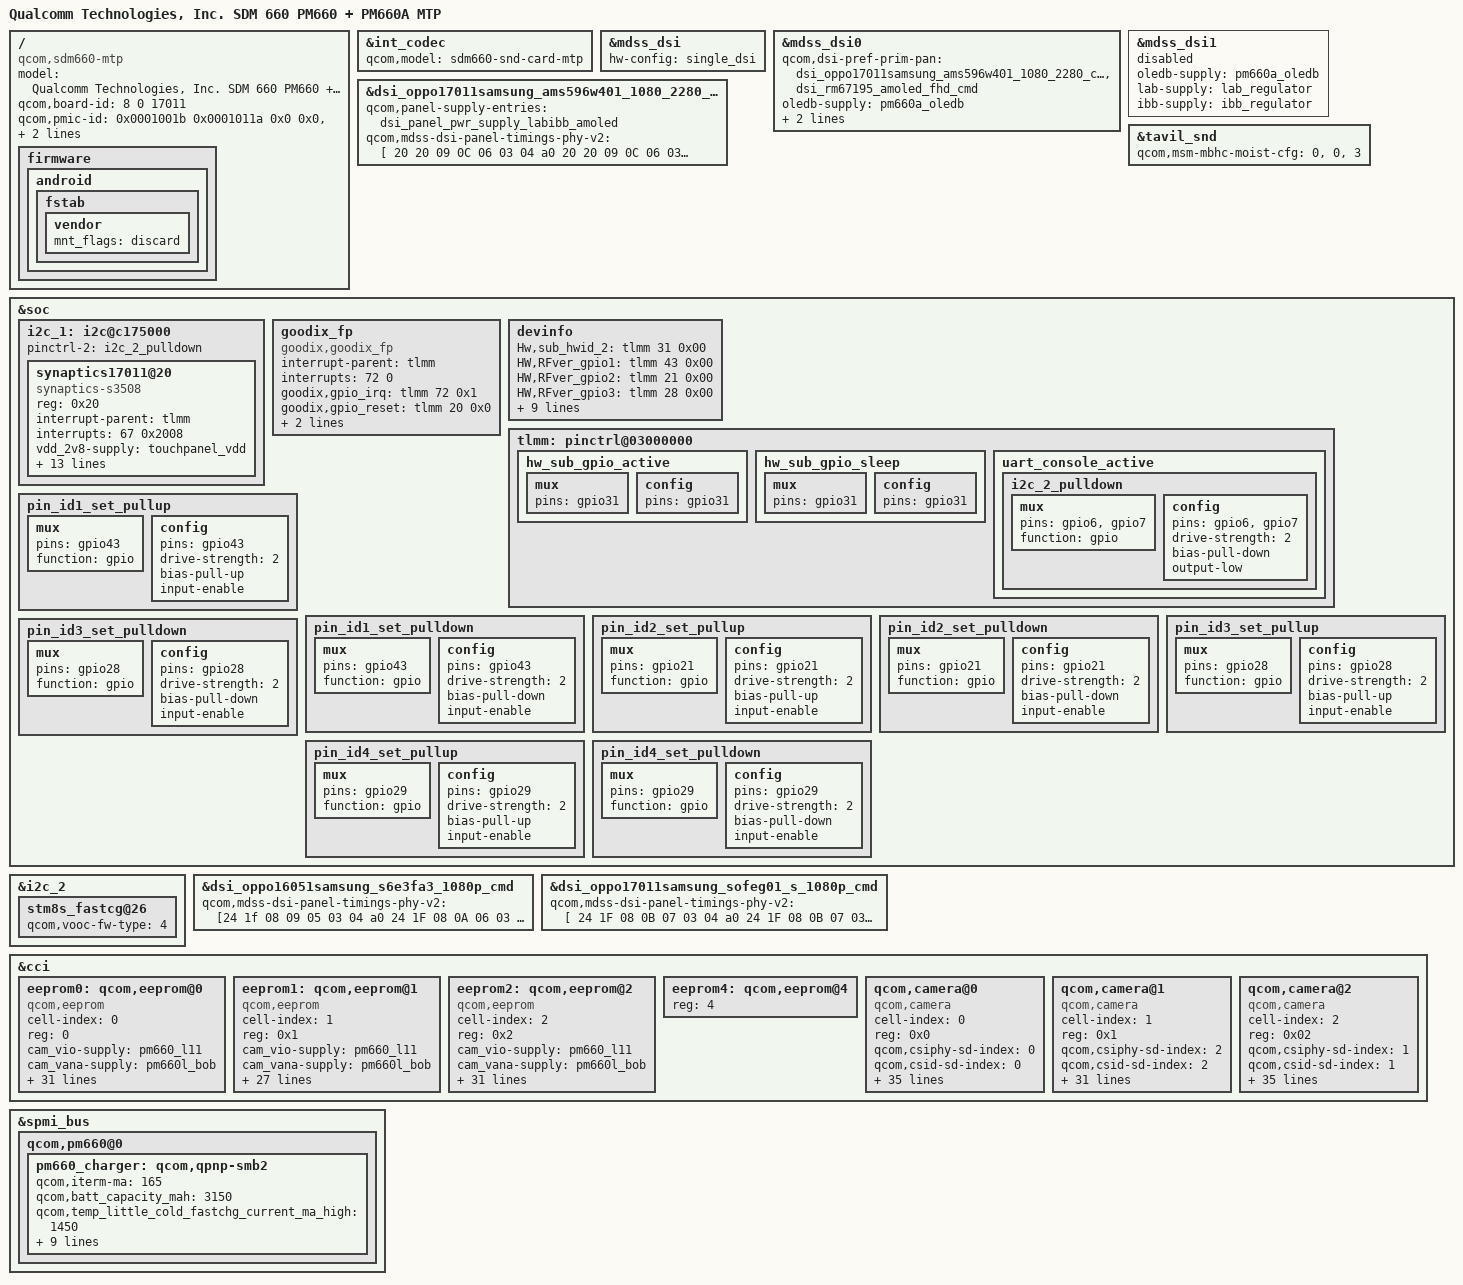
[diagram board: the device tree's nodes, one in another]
/* Copyright (c) 2016-2017, The Linux Foundation. All rights reserved.
 *
 * This program is free software; you can redistribute it and/or modify
 * it under the terms of the GNU General Public License version 2 and
 * only version 2 as published by the Free Software Foundation.
 *
 * This program is distributed in the hope that it will be useful,
 * but WITHOUT ANY WARRANTY; without even the implied warranty of
 * MERCHANTABILITY or FITNESS FOR A PARTICULAR PURPOSE.  See the
 * GNU General Public License for more details.
 */


/dts-v1/;

#include "sdm660.dtsi"
#include "sdm660-mtp.dtsi"
#include "msm-pm660a.dtsi"
//#ifndef VENDOR_EDIT
/*xiang.fei@PSW.MM.AudioDriver.Machine, 2017/01/26, Mofidy for audio config*/
//#include "sdm660-external-codec.dtsi"
//#else /* VENDOR_EDIT */
#include "sdm660-internal-codec.dtsi"
//#endif /* VENDOR_EDIT */

#include "dsi-panel-oppo17011samsung_ams596w401_1080_2280_cmd.dtsi"

/ {
	model = "Qualcomm Technologies, Inc. SDM 660 PM660 + PM660A MTP";
	compatible = "qcom,sdm660-mtp", "qcom,sdm660", "qcom,mtp";
	qcom,board-id = <8 0 17011>;
	qcom,pmic-id = <0x0001001b 0x0001011a 0x0 0x0>,
			<0x0001001b 0x0002001a 0x0 0x0>,
			<0x0001001b 0x0202001a 0x0 0x0>;
	
	firmware: firmware {
		android {
			fstab {
				vendor {
					mnt_flags = "discard";
				};
			};
		};
	};
};

//#ifdef VENDOR_EDIT
/*xiang.fei@PSW.MM.AudioDriver.Machine, 2017/01/26, Add for audio config*/
&int_codec {
	qcom,model = "sdm660-snd-card-mtp";
};
//#endif /* VENDOR_EDIT */

&mdss_dsi {
	hw-config = "single_dsi";
};

&mdss_dsi0 {
	qcom,dsi-pref-prim-pan = <&dsi_oppo17011samsung_ams596w401_1080_2280_cmd &dsi_rm67195_amoled_fhd_cmd>;
	oledb-supply = <&pm660a_oledb>;
	lab-supply = <&lab_regulator>;
	ibb-supply = <&ibb_regulator>;
};

&dsi_oppo17011samsung_ams596w401_1080_2280_cmd {
	qcom,panel-supply-entries = <&dsi_panel_pwr_supply_labibb_amoled>;
};

&mdss_dsi1 {
	status = "disabled";
	oledb-supply = <&pm660a_oledb>;
	lab-supply = <&lab_regulator>;
	ibb-supply = <&ibb_regulator>;
};

&tavil_snd {
	qcom,msm-mbhc-moist-cfg = <0>, <0>, <3>;
};

&soc {
	i2c_1: i2c@c175000 {
		status = "disabled";
	};

    i2c_1: i2c@c175000 {
		pinctrl-names = "i2c_pulldown";
		pinctrl-2 = <&i2c_2_pulldown>;
	};

	goodix_fp {
        compatible = "goodix,goodix_fp";
        interrupt-parent = <&tlmm>;
        interrupts = <72 0>;
        goodix,gpio_irq = <&tlmm 72 0x1>;
        goodix,gpio_reset = <&tlmm 20 0x0>;
        ldo5-supply = <&pm660l_l5>;  // pm660l_l5 for goodix_fp
        pinctrl-names = "default";
        pinctrl-0 = <&gpio_goodix_irq_default>;
    };

	devinfo {
		Hw,sub_hwid_2 = <&tlmm 31 0x00>;
		HW,RFver_gpio1 = <&tlmm 43 0x00>;
		HW,RFver_gpio2 = <&tlmm 21 0x00>;
		HW,RFver_gpio3 = <&tlmm 28 0x00>;
		HW,RFver_gpio4 = <&tlmm 29 0x00>;
		pinctrl-names = "gpio_HW_ID1_pullup","gpio_HW_ID1_pulldown",
						"gpio_HW_ID2_pullup", "gpio_HW_ID2_pulldown",
						"gpio_HW_ID3_pullup", "gpio_HW_ID3_pulldown",
						"gpio_HW_ID4_pullup", "gpio_HW_ID4_pulldown";
		
		pinctrl-2 = <&pin_id1_set_pullup>;
		pinctrl-3 = <&pin_id1_set_pulldown>;
		pinctrl-4 = <&pin_id2_set_pullup>;
		pinctrl-5 = <&pin_id2_set_pulldown>;
		pinctrl-6 = <&pin_id3_set_pullup>;
		pinctrl-7 = <&pin_id3_set_pulldown>;
		pinctrl-8 = <&pin_id4_set_pullup>;
		pinctrl-9 = <&pin_id4_set_pulldown>;
	};

	tlmm: pinctrl@03000000 {
	    hw_sub_gpio_active: hw_sub_gpio_active {
			/* active state */
			mux {
				pins = "gpio31";
			};
			config {
				pins = "gpio31";
			};
		};
        
		hw_sub_gpio_sleep: hw_sub_gpio_sleep {
			/* sleep state */
			mux {
				pins = "gpio31";
			};
			config {
				pins = "gpio31";
			};
		};

		uart_console_active: uart_console_active {
			i2c_2_pulldown: i2c_2_pulldown {
				mux {
					pins = "gpio6", "gpio7";
					function = "gpio";
				};

				config {
					pins = "gpio6", "gpio7";
					drive-strength = <2>;
					bias-pull-down;
					output-low;
				};
			};
		};
	};

		pin_id1_set_pullup: pin_id1_set_pullup {
			mux {
				pins = "gpio43";
				function = "gpio";
			};
			config {
				pins = "gpio43";
				drive-strength = <2>;
				bias-pull-up;
				input-enable;
			};
		};

		pin_id1_set_pulldown: pin_id1_set_pulldown {
			mux {
				pins = "gpio43";
				function = "gpio";
			};
			config {
				pins = "gpio43";
				drive-strength = <2>;
				bias-pull-down;
				input-enable;
			};
		};

		pin_id2_set_pullup: pin_id2_set_pullup {
			mux {
				pins = "gpio21";
				function = "gpio";
			};
			config {
				pins = "gpio21";
				drive-strength = <2>;
				bias-pull-up;
				input-enable;
			};
		};

		pin_id2_set_pulldown: pin_id2_set_pulldown {
			mux {
				pins = "gpio21";
				function = "gpio";
			};
			config {
				pins = "gpio21";
				drive-strength = <2>;
				bias-pull-down;
				input-enable;
			};
		};

		pin_id3_set_pullup: pin_id3_set_pullup {
			mux {
				pins = "gpio28";
				function = "gpio";
			};
			config {
				pins = "gpio28";
				drive-strength = <2>;
				bias-pull-up;
				input-enable;
			};
		};

		pin_id3_set_pulldown: pin_id3_set_pulldown {
			mux {
				pins = "gpio28";
				function = "gpio";
			};
			config {
				pins = "gpio28";
				drive-strength = <2>;
				bias-pull-down;
				input-enable;
			};
		};

		pin_id4_set_pullup: pin_id4_set_pullup {
			mux {
				pins = "gpio29";
				function = "gpio";
			};
			config {
				pins = "gpio29";
				drive-strength = <2>;
				bias-pull-up;
				input-enable;
			};
		};

		pin_id4_set_pulldown: pin_id4_set_pulldown {
			mux {
				pins = "gpio29";
				function = "gpio";
			};
			config {
				pins = "gpio29";
				drive-strength = <2>;
				bias-pull-down;
				input-enable;
			};
		};
};

&i2c_1 {
	status = "okay";
	synaptics17011@20 {
		compatible = "synaptics-s3508";
		reg = <0x20>;

		/* Interrupt && Irq-gpio */
		interrupt-parent = <&tlmm>;
		interrupts = <67 0x2008>;

		
		/* Power Config */
		//enable2v8_gpio = <&tlmm 15 0x1>;
		vdd_2v8-supply = <&touchpanel_vdd>;
		vcc_1v8-supply = <&pm660_l14>;

		/* Other HW Resource */
		irq-gpio = <&tlmm 67 0x2008>;
		reset-gpio = <&tlmm 66 0x1>;
		pinctrl-names = "default";
		pinctrl-0 = <&ts_int_active &ts_reset_active>;

		touchpanel,max-num-support = <10>;
		touchpanel,tx-rx-num = <15 30>;
		touchpanel,panel-coords = <1080 2160>;
		touchpanel,display-coords = <1080 2160>;

		/* SW Support Feature Control */
		black_gesture_support;
		edge_limit_support;
		smart_gesture_support;
		//pressure_report_support;
		/*
		 *Virtual Key Config:
		 *1:touchpanel,button-type: <virtualkey_type  supportted_button-map>
		 *virtualkey_type:
		 *Type 1: using board_properties
		 *Type 2: using same IC (button zone&& touch zone are seprate)
		 *Type 3: using diffrent IC (button zone&& touch zone are seprate)
		 *Type 4: No need of virtual key process
		 *supportted_button-map:select|menu|home|back
		 *
		 *2:touchpanel,button-map
		 *type (X1,Y1)(X2,Y2)(X3,Y3)(Width_X,Hight_Y)--Only when button-type is 0
		 */
		touchpanel,button-type = <4>;
		touchpanel.button-TRx = <0 0>;
	};
};

&i2c_2 {
	stm8s_fastcg@26{
		qcom,vooc-fw-type = <4>;
	};
};

&dsi_oppo16051samsung_s6e3fa3_1080p_cmd {
	qcom,mdss-dsi-panel-timings-phy-v2 = [24 1f 08 09 05 03 04 a0
		24 1F 08 0A 06 03 04 a0
		24 1F 08 0A 06 03 04 a0
		24 1F 08 0A 06 03 04 a0
		24 1F 08 0A 06 03 04 a0
		24 1B 08 0A 06 03 04 a0];
};

&dsi_oppo17011samsung_sofeg01_s_1080p_cmd {
	qcom,mdss-dsi-panel-timings-phy-v2 = [
		24 1F 08 0B 07 03 04 a0
		24 1F 08 0B 07 03 04 a0
		24 1F 08 0B 07 03 04 a0
		24 1F 08 0B 07 03 04 a0
		24 1F 08 0B 07 03 04 a0];
};


&dsi_oppo17011samsung_ams596w401_1080_2280_cmd {
	qcom,mdss-dsi-panel-timings-phy-v2 = [
		20 20 09 0C 06 03 04 a0
		20 20 09 0C 06 03 04 a0
		20 20 09 0C 06 03 04 a0
		20 20 09 0C 06 03 04 a0
		20 1E 09 0A 06 03 04 a0];
};

&cci {
	eeprom0: qcom,eeprom@0 {
		cell-index = <0>;
		reg = <0>;
		compatible = "qcom,eeprom";
		cam_vio-supply = <&pm660_l11>;
		cam_vana-supply = <&pm660l_bob>;
		cam_vdig-supply = <&pm660_s5>;
		qcom,cam-vreg-name = "cam_vio", "cam_vana", "cam_vdig";
		qcom,cam-vreg-min-voltage = <1780000 3300000 1350000>;
		qcom,cam-vreg-max-voltage = <1950000 3600000 1350000>;
		qcom,cam-vreg-op-mode = <105000 80000 105000>;
		qcom,gpio-no-mux = <0>;
		pinctrl-names = "cam_default", "cam_suspend";
		pinctrl-0 = <&cam_sensor_mclk0_active
				&cam_sensor_rear_active
				&cam_actuator_vaf_active>;
		pinctrl-1 = <&cam_sensor_mclk0_suspend
				&cam_sensor_rear_suspend
				&cam_actuator_vaf_suspend>;
		gpios = <&tlmm 32 0>,
			<&tlmm 46 0>,
			<&pm660l_gpios 4 0>,
			<&tlmm 51 0>,
			<&tlmm 50 0>;
		qcom,gpio-reset = <1>;
		qcom,gpio-vdig = <2>;
		qcom,gpio-vana = <3>;
		qcom,gpio-vaf = <4>;
		qcom,gpio-req-tbl-num = <0 1 2 3 4>;
		qcom,gpio-req-tbl-flags = <1 0 0 0 0>;
		qcom,gpio-req-tbl-label = "CAMIF_MCLK0",
					"CAM_RESET0",
					"CAM_VDIG",
					"CAM_VANA",
					"CAM_VAF";
		qcom,sensor-position = <0>;
		qcom,sensor-mode = <0>;
		qcom,cci-master = <0>;
		status = "ok";
		clocks = <&clock_mmss MCLK0_CLK_SRC>,
				<&clock_mmss MMSS_CAMSS_MCLK0_CLK>;
		clock-names = "cam_src_clk", "cam_clk";
		qcom,clock-rates = <24000000 0>;
	};

	eeprom1: qcom,eeprom@1 {
		cell-index = <1>;
		reg = <0x1>;
		compatible = "qcom,eeprom";
		cam_vio-supply = <&pm660_l11>;
		cam_vana-supply = <&pm660l_bob>;
		cam_vdig-supply = <&pm660_s5>;
		qcom,cam-vreg-name = "cam_vio", "cam_vana", "cam_vdig";
		qcom,cam-vreg-min-voltage = <1780000 3300000 1350000>;
		qcom,cam-vreg-max-voltage = <1950000 3600000 1350000>;
		qcom,cam-vreg-op-mode = <105000 80000 105000>;
		qcom,gpio-no-mux = <0>;
		pinctrl-names = "cam_default", "cam_suspend";
		pinctrl-0 = <&cam_sensor_mclk2_active
			&cam_sensor_rear2_active>;
		pinctrl-1 = <&cam_sensor_mclk2_suspend
			&cam_sensor_rear2_suspend>;
		gpios = <&tlmm 34 0>,
		    <&tlmm 48 0>,
		    <&pm660l_gpios 3 0>;
		    //<&tlmm 51 0>;
		qcom,gpio-reset = <1>;
		qcom,gpio-vdig = <2>;
		qcom,gpio-vana = <3>;
		qcom,gpio-req-tbl-num = <0 1 2 3>;
		qcom,gpio-req-tbl-flags = <1 0 0 0>;
		qcom,gpio-req-tbl-label = "CAMIF_MCLK",
				"CAM_RESET",
				"CAM_VDIG",
				"CAM_VANA";
		qcom,sensor-position = <0>;
		qcom,sensor-mode = <0>;
		qcom,cci-master = <1>;
		status = "ok";
		clocks = <&clock_mmss MCLK2_CLK_SRC>,
		    <&clock_mmss MMSS_CAMSS_MCLK2_CLK>;
		clock-names = "cam_src_clk", "cam_clk";
		qcom,clock-rates = <24000000 0>;
	};

	eeprom2: qcom,eeprom@2 {
		cell-index = <2>;
		reg = <0x2>;
		compatible = "qcom,eeprom";
		cam_vio-supply = <&pm660_l11>;
		cam_vana-supply = <&pm660l_bob>;
		cam_vdig-supply = <&pm660_s5>;
		qcom,cam-vreg-name = "cam_vio", "cam_vana", "cam_vdig";
		qcom,cam-vreg-min-voltage = <1780000 3300000 1350000>;
		qcom,cam-vreg-max-voltage = <1950000 3600000 1350000>;
		qcom,cam-vreg-op-mode = <105000 80000 105000>;
		qcom,gpio-no-mux = <0>;
		pinctrl-names = "cam_default", "cam_suspend";
		pinctrl-0 = <&cam_sensor_mclk1_active
				 &cam_sensor_front_active
				&cam_actuator_vaf_active>;
		pinctrl-1 = <&cam_sensor_mclk1_suspend
				 &cam_sensor_front_suspend
				&cam_actuator_vaf_suspend>;
		gpios = <&tlmm 33 0>,
			<&tlmm 47 0>,
			<&pm660_gpios 3 0>,
			//<&tlmm 44 0>,
			<&tlmm 50 0>;
		qcom,gpio-reset = <1>;
		qcom,gpio-vdig = <2>;
		qcom,gpio-vana = <3>;
		qcom,gpio-vaf = <4>;
		qcom,gpio-req-tbl-num = <0 1 2 3 4>;
		qcom,gpio-req-tbl-flags = <1 0 0 0 0>;
		qcom,gpio-req-tbl-label = "CAMIF_MCLK2",
					"CAM_RESET2",
					"CAM_VDIG",
					"CAM_VANA",
					"CAM_VAF";
		qcom,sensor-position = <1>;
		qcom,sensor-mode = <0>;
		qcom,cci-master = <1>;
		status = "ok";
		clocks = <&clock_mmss MCLK1_CLK_SRC>,
			<&clock_mmss MMSS_CAMSS_MCLK1_CLK>;
		clock-names = "cam_src_clk", "cam_clk";
		qcom,clock-rates = <24000000 0>;
	};

	eeprom4: qcom,eeprom@4 {
		reg = <4>;
	};

	qcom,camera@0 {
		cell-index = <0>;
		compatible = "qcom,camera";
		reg = <0x0>;
		qcom,csiphy-sd-index = <0>;
		qcom,csid-sd-index = <0>;
		qcom,mount-angle = <270>;
		qcom,led-flash-src = <&led_flash0>;
		qcom,actuator-src = <&actuator0>;
		//qcom,ois-src = <&ois0>;
		qcom,eeprom-src = <&eeprom0 &eeprom4>;
		cam_vio-supply = <&pm660_l11>;
		cam_vana-supply = <&pm660l_bob>;
		cam_vdig-supply = <&pm660_s5>;
		qcom,cam-vreg-name = "cam_vio", "cam_vana", "cam_vdig";
		qcom,cam-vreg-min-voltage = <1780000 3300000 1350000>;
		qcom,cam-vreg-max-voltage = <1950000 3600000 1350000>;
		qcom,cam-vreg-op-mode = <105000 80000 105000>;
		qcom,gpio-no-mux = <0>;
		pinctrl-names = "cam_default", "cam_suspend";
		pinctrl-0 = <&cam_sensor_mclk0_active
				 &cam_sensor_rear_active>;
		pinctrl-1 = <&cam_sensor_mclk0_suspend
				 &cam_sensor_rear_suspend>;
		gpios = <&tlmm 32 0>,
			<&tlmm 48 0>,
			<&pm660l_gpios 4 0>,
			<&tlmm 50 0>,
			<&tlmm 1 0>;
		qcom,gpio-reset = <1>;
		qcom,gpio-vdig = <2>;
		qcom,gpio-vana = <3>;
		qcom,gpio-vaf = <4>;
		qcom,gpio-req-tbl-num = <0 1 2 3 4>;
		qcom,gpio-req-tbl-flags = <1 0 0 0 0>;
		qcom,gpio-req-tbl-label = "CAMIF_MCLK0",
					"CAM_RESET0",
					"CAM_VDIG",
					"CAM_VANA",
					"CAM_VAF";
		qcom,sensor-position = <0>;
		qcom,sensor-mode = <0>;
		qcom,cci-master = <0>;
		status = "ok";
		clocks = <&clock_mmss MCLK0_CLK_SRC>,
				<&clock_mmss MMSS_CAMSS_MCLK0_CLK>;
		clock-names = "cam_src_clk", "cam_clk";
		qcom,clock-rates = <24000000 0>;
	};

    qcom,camera@1 {
		cell-index = <1>;
		compatible = "qcom,camera";
		reg = <0x1>;
		qcom,csiphy-sd-index = <2>;
		qcom,csid-sd-index = <2>;
		qcom,mount-angle = <90>;
		//qcom,actuator-src = <&actuator1>;
		qcom,eeprom-src = <&eeprom1>;
		cam_vio-supply = <&pm660_l11>;
		cam_vana-supply = <&pm660l_bob>;
		cam_vdig-supply = <&pm660_s5>;
		qcom,cam-vreg-name = "cam_vio", "cam_vana", "cam_vdig";
		qcom,cam-vreg-min-voltage = <1780000 3300000 1350000>;
		qcom,cam-vreg-max-voltage = <1950000 3600000 1350000>;
		qcom,cam-vreg-op-mode = <105000 80000 105000>;
		qcom,gpio-no-mux = <0>;
		pinctrl-names = "cam_default", "cam_suspend";
		pinctrl-0 = <&cam_sensor_mclk2_active
				 &cam_sensor_front_active>;
		pinctrl-1 = <&cam_sensor_mclk2_suspend
				 &cam_sensor_front_suspend>;
		gpios = <&tlmm 34 0>,
			<&tlmm 47 0>,
			<&tlmm 64 0>,
			<&tlmm 35 0>;
		qcom,gpio-reset = <1>;
		qcom,gpio-vdig = <2>;
		qcom,gpio-vana = <3>;
		qcom,gpio-req-tbl-num = <0 1 2 3>;
		qcom,gpio-req-tbl-flags = <1 0 0 0>;
		qcom,gpio-req-tbl-label = "CAMIF_MCLK",
					  "CAM_RESET",
					  "CAM_VDIG",
					  "CAM_VANA";
		qcom,sensor-position = <1>;
		qcom,sensor-mode = <0>;
		qcom,cci-master = <0>;
		status = "ok";
		clocks = <&clock_mmss MCLK2_CLK_SRC>,
			<&clock_mmss MMSS_CAMSS_MCLK2_CLK>;
		clock-names = "cam_src_clk", "cam_clk";
		qcom,clock-rates = <24000000 0>;
	};

	qcom,camera@2 {
		cell-index = <2>;
		compatible = "qcom,camera";
		reg = <0x02>;
		qcom,csiphy-sd-index = <1>;
		qcom,csid-sd-index = <1>;
		qcom,mount-angle = <90>;
		qcom,led-flash-src = <&led_flash0>;
		qcom,actuator-src = <&actuator2>;
		qcom,eeprom-src = <&eeprom2 &eeprom3>;
		cam_vio-supply = <&pm660_l11>;
		cam_vana-supply = <&pm660l_bob>;
		cam_vdig-supply = <&pm660_s5>;
		qcom,cam-vreg-name = "cam_vio", "cam_vana", "cam_vdig";
		qcom,cam-vreg-min-voltage = <1780000 3300000 1350000>;
		qcom,cam-vreg-max-voltage = <1950000 3600000 1350000>;
		qcom,cam-vreg-op-mode = <105000 80000 105000>;
		qcom,gpio-no-mux = <0>;
		pinctrl-names = "cam_default", "cam_suspend";
		pinctrl-0 = <&cam_sensor_mclk1_active
				 &cam_sensor_rear2_active>;
		pinctrl-1 = <&cam_sensor_mclk1_suspend
				 &cam_sensor_rear2_suspend>;
		gpios = <&tlmm 33 0>,
			<&tlmm 46 0>,
			<&pm660l_gpios 3 0>,
			<&tlmm 35 0>,
			<&tlmm 0 0>;
		qcom,gpio-reset = <1>;
		qcom,gpio-vdig = <2>;
		qcom,gpio-vana = <3>;
		qcom,gpio-vaf = <4>;
		qcom,gpio-req-tbl-num = <0 1 2 3 4>;
		qcom,gpio-req-tbl-flags = <1 0 0 0 0>;
		qcom,gpio-req-tbl-label = "CAMIF_MCLK2",
					"CAM_RESET2",
					"CAM_VDIG",
					"CAM_VANA",
					"CAM_VAF";
		qcom,sensor-position = <2>;
		qcom,sensor-mode = <0>;
		qcom,cci-master = <1>;
		status = "ok";
		clocks = <&clock_mmss MCLK1_CLK_SRC>,
			<&clock_mmss MMSS_CAMSS_MCLK1_CLK>;
		clock-names = "cam_src_clk", "cam_clk";
		qcom,clock-rates = <24000000 0>;
	};
};

&spmi_bus {
	qcom,pm660@0 {
		pm660_charger: qcom,qpnp-smb2 {
			qcom,iterm-ma = <165>;
			qcom,batt_capacity_mah = <3150>;
			qcom,temp_little_cold_fastchg_current_ma_high = <1450>;	/*0.95*0.5C 1503.5~1567.5*/
			qcom,temp_little_cold_fastchg_current_ma_low = <850>;	/*0.95*0.3C 876.5~940.5*/
			qcom,temp_little_cold_fastchg_current_ma = <850>;		/* 0.15C = 495*/
			qcom,temp_cool_fastchg_current_ma_high = <2000>;			/* 0.25C = 825 */ /*0.95*0.7C 2130.5~2194.5*/
			qcom,temp_cool_fastchg_current_ma_low = <1450>;			/* 0.15C = 495 */ /*0.95*0.5C 1503.5~1567.5*/
			qcom,temp_warm_fastchg_current_ma = <850>;				/* 0.25C = 825 */ /*0.3C 876.5~940.5*/
			qcom,usbid-gpio = <&tlmm 49 0x00>;
			pinctrl-names = "usbid_active", "usbid_sleep";
			pinctrl-3 = <&usbid_active>;
			pinctrl-4 = <&usbid_sleep>;
		};
	};
};			
